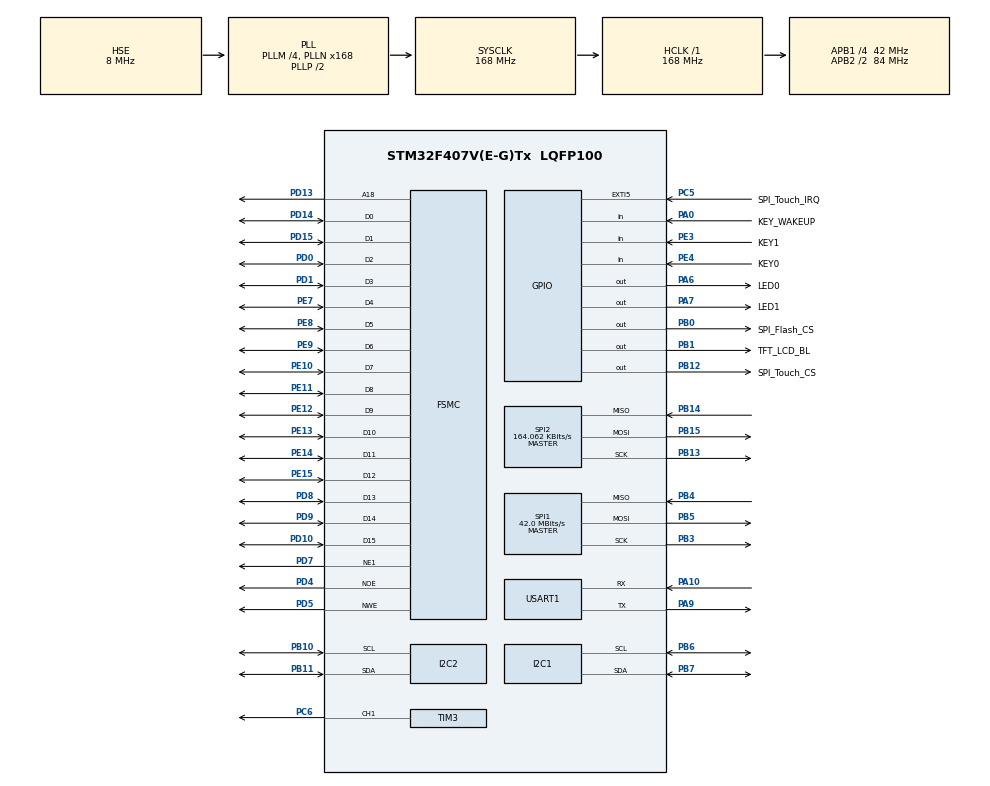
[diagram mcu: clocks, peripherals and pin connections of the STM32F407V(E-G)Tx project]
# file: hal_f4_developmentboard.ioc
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FSMC.AddressSetupTime1=2
FSMC.DataSetupTime1=5
I2C2.I2C_Mode=I2C_Standard
Mcu.Family=STM32F4
Mcu.Name=STM32F407V(E-G)Tx
Mcu.Package=LQFP100
NVIC.PriorityGroup=NVIC_PRIORITYGROUP_4
NVIC.TIM6_DAC_IRQn=true\:5\:0\:true\:false\:true\:true\:true\:true
PA0-WKUP.GPIO_Label=KEY_WAKEUP
PA0-WKUP.GPIO_PuPd=GPIO_PULLDOWN
PA0-WKUP.Signal=GPIO_Input
PA10.Mode=Asynchronous
PA10.Signal=USART1_RX
PA13.Mode=Serial_Wire
PA13.Signal=SYS_JTMS-SWDIO
PA14.Mode=Serial_Wire
PA14.Signal=SYS_JTCK-SWCLK
PA6.GPIO_Label=LED0
PA6.PinState=GPIO_PIN_SET
PA6.Signal=GPIO_Output
PA7.GPIO_Label=LED1
PA7.PinState=GPIO_PIN_SET
PA7.Signal=GPIO_Output
PA9.Mode=Asynchronous
PA9.Signal=USART1_TX
PB0.GPIO_Label=SPI_Flash_CS
PB0.Signal=GPIO_Output
PB1.GPIO_Label=TFT_LCD_BL
PB1.Signal=GPIO_Output
PB10.Mode=I2C
PB10.Signal=I2C2_SCL
PB11.Mode=I2C
PB11.Signal=I2C2_SDA
PB12.GPIO_Label=SPI_Touch_CS
PB12.Signal=GPIO_Output
PB13.Mode=Full_Duplex_Master
PB13.Signal=SPI2_SCK
PB14.Mode=Full_Duplex_Master
PB14.Signal=SPI2_MISO
PB15.Mode=Full_Duplex_Master
PB15.Signal=SPI2_MOSI
PB3.Mode=Full_Duplex_Master
PB3.Signal=SPI1_SCK
PB4.Mode=Full_Duplex_Master
PB4.Signal=SPI1_MISO
PB5.Mode=Full_Duplex_Master
PB5.Signal=SPI1_MOSI
PB6.Mode=I2C
PB6.Signal=I2C1_SCL
PB7.Mode=I2C
PB7.Signal=I2C1_SDA
PC5.GPIO_Label=SPI_Touch_IRQ
PC5.Signal=GPXTI5
PC6.Signal=S_TIM3_CH1
PD0.Mode=16b-d1
PD0.Signal=FSMC_D2
PD1.Mode=16b-d1
PD1.Signal=FSMC_D3
PD10.Mode=16b-d1
PD10.Signal=FSMC_D15
PD13.Mode=A18_1
PD13.Signal=FSMC_A18
PD14.Mode=16b-d1
PD14.Signal=FSMC_D0
PD15.Mode=16b-d1
PD15.Signal=FSMC_D1
PD4.Mode=Lcd1
PD4.Signal=FSMC_NOE
PD5.Mode=Lcd1
PD5.Signal=FSMC_NWE
PD7.Mode=NorPsramChipSelect1_1
PD7.Signal=FSMC_NE1
PD8.Mode=16b-d1
PD8.Signal=FSMC_D13
PD9.Mode=16b-d1
PD9.Signal=FSMC_D14
PE10.Mode=16b-d1
PE10.Signal=FSMC_D7
PE11.Mode=16b-d1
PE11.Signal=FSMC_D8
PE12.Mode=16b-d1
PE12.Signal=FSMC_D9
PE13.Mode=16b-d1
PE13.Signal=FSMC_D10
PE14.Mode=16b-d1
PE14.Signal=FSMC_D11
PE15.Mode=16b-d1
PE15.Signal=FSMC_D12
PE3.GPIO_Label=KEY1
PE3.GPIO_PuPd=GPIO_PULLUP
PE3.Signal=GPIO_Input
PE4.GPIO_Label=KEY0
PE4.GPIO_PuPd=GPIO_PULLUP
PE4.Signal=GPIO_Input
PE7.Mode=16b-d1
PE7.Signal=FSMC_D4
PE8.Mode=16b-d1
PE8.Signal=FSMC_D5
PE9.Mode=16b-d1
PE9.Signal=FSMC_D6
PH0-OSC_IN.Mode=HSE-External-Oscillator
PH0-OSC_IN.Signal=RCC_OSC_IN
PH1-OSC_OUT.Mode=HSE-External-Oscillator
PH1-OSC_OUT.Signal=RCC_OSC_OUT
ProjectManager.HeapSize=0x200
ProjectManager.StackSize=0x800
ProjectManager.TargetToolchain=MDK-ARM V5.32
RCC.48MHZClocksFreq_Value=84000000
RCC.AHBFreq_Value=168000000
RCC.APB1CLKDivider=RCC_HCLK_DIV4
RCC.APB1Freq_Value=42000000
RCC.APB1TimFreq_Value=84000000
RCC.APB2CLKDivider=RCC_HCLK_DIV2
RCC.APB2Freq_Value=84000000
RCC.APB2TimFreq_Value=168000000
RCC.CortexFreq_Value=168000000
RCC.HCLKFreq_Value=168000000
RCC.HSE_VALUE=8000000
RCC.HSI_VALUE=16000000
RCC.LSE_VALUE=32768
RCC.PLLM=4
RCC.PLLN=168
RCC.PLLSourceVirtual=RCC_PLLSOURCE_HSE
RCC.SYSCLKFreq_VALUE=168000000
RCC.SYSCLKSource=RCC_SYSCLKSOURCE_PLLCLK
RCC.VCOOutputFreq_Value=336000000
SH.S_TIM3_CH1.0=TIM3_CH1,PWM Generation1 CH1
SPI1.CalculateBaudRate=42.0 MBits/s
SPI1.Direction=SPI_DIRECTION_2LINES
SPI1.Mode=SPI_MODE_MASTER
SPI1.VirtualType=VM_MASTER
SPI2.BaudRatePrescaler=SPI_BAUDRATEPRESCALER_256
SPI2.CalculateBaudRate=164.062 KBits/s
SPI2.Direction=SPI_DIRECTION_2LINES
SPI2.Mode=SPI_MODE_MASTER
SPI2.VirtualType=VM_MASTER
TIM3.AutoReloadPreload=TIM_AUTORELOAD_PRELOAD_ENABLE
TIM3.Channel-PWM\ Generation1\ CH1=TIM_CHANNEL_1
TIM3.Period=19999
TIM3.Prescaler=83
TIM3.Pulse-PWM\ Generation1\ CH1=0
TIM6.AutoReloadPreload=TIM_AUTORELOAD_PRELOAD_ENABLE
TIM6.Period=4999
TIM6.Prescaler=83
USART1.VirtualMode=VM_ASYNC
VP_TIM3_VS_ClockSourceINT.Mode=Internal
VP_TIM6_VS_ClockSourceINT.Mode=Enable_Timer
board=custom

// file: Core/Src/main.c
/* USER CODE BEGIN Header */
/**
  ******************************************************************************
  * @file           : main.c
  * @brief          : Main program body
  ******************************************************************************
  * @attention
  *
  * Copyright (c) 2023 STMicroelectronics.
  * All rights reserved.
  *
  * This software is licensed under terms that can be found in the LICENSE file
  * in the root directory of this software component.
  * If no LICENSE file comes with this software, it is provided AS-IS.
  *
  ******************************************************************************
  */
/* USER CODE END Header */
#include "main.h"
#include "i2c.h"
#include "spi.h"
#include "tim.h"
#include "usart.h"
#include "gpio.h"
#include "fsmc.h"

/* USER CODE BEGIN Includes */
#include "MyApplication.h"
/* USER CODE END Includes */

void SystemClock_Config(void);

int main(void)
{

  /* MCU Configuration--------------------------------------------------------*/

  /* Reset of all peripherals, Initializes the Flash interface and the Systick. */
  HAL_Init();

  /* Configure the system clock */
  SystemClock_Config();

  /* Initialize all configured peripherals */
  MX_GPIO_Init();
  MX_USART1_UART_Init();
  MX_SPI1_Init();
  MX_TIM6_Init();
  MX_FSMC_Init();
  MX_SPI2_Init();
  MX_I2C1_Init();
  MX_I2C2_Init();
  MX_TIM3_Init();
  /* USER CODE BEGIN 2 */
  MyInit.Peripheral_Set();
  /* USER CODE END 2 */

  /* Infinite loop */
  /* USER CODE BEGIN WHILE */
  while (1)
  {
			System.Run();
    /* USER CODE END WHILE */

  }
}

void SystemClock_Config(void)
{
  RCC_OscInitTypeDef RCC_OscInitStruct = {0};
  RCC_ClkInitTypeDef RCC_ClkInitStruct = {0};

  /** Configure the main internal regulator output voltage
  */
  __HAL_RCC_PWR_CLK_ENABLE();
  __HAL_PWR_VOLTAGESCALING_CONFIG(PWR_REGULATOR_VOLTAGE_SCALE1);

  /** Initializes the RCC Oscillators according to the specified parameters
  * in the RCC_OscInitTypeDef structure.
  */
  RCC_OscInitStruct.OscillatorType = RCC_OSCILLATORTYPE_HSE;
  RCC_OscInitStruct.HSEState = RCC_HSE_ON;
  RCC_OscInitStruct.PLL.PLLState = RCC_PLL_ON;
  RCC_OscInitStruct.PLL.PLLSource = RCC_PLLSOURCE_HSE;
  RCC_OscInitStruct.PLL.PLLM = 4;
  RCC_OscInitStruct.PLL.PLLN = 168;
  RCC_OscInitStruct.PLL.PLLP = RCC_PLLP_DIV2;
  RCC_OscInitStruct.PLL.PLLQ = 4;
  if (HAL_RCC_OscConfig(&RCC_OscInitStruct) != HAL_OK)
  {
    Error_Handler();
  }

  /** Initializes the CPU, AHB and APB buses clocks
  */
  RCC_ClkInitStruct.ClockType = RCC_CLOCKTYPE_HCLK|RCC_CLOCKTYPE_SYSCLK
                              |RCC_CLOCKTYPE_PCLK1|RCC_CLOCKTYPE_PCLK2;
  RCC_ClkInitStruct.SYSCLKSource = RCC_SYSCLKSOURCE_PLLCLK;
  RCC_ClkInitStruct.AHBCLKDivider = RCC_SYSCLK_DIV1;
  RCC_ClkInitStruct.APB1CLKDivider = RCC_HCLK_DIV4;
  RCC_ClkInitStruct.APB2CLKDivider = RCC_HCLK_DIV2;

  if (HAL_RCC_ClockConfig(&RCC_ClkInitStruct, FLASH_LATENCY_5) != HAL_OK)
  {
    Error_Handler();
  }
}

void Error_Handler(void)
{
  __disable_irq();
  while (1)
  {
  }
}
